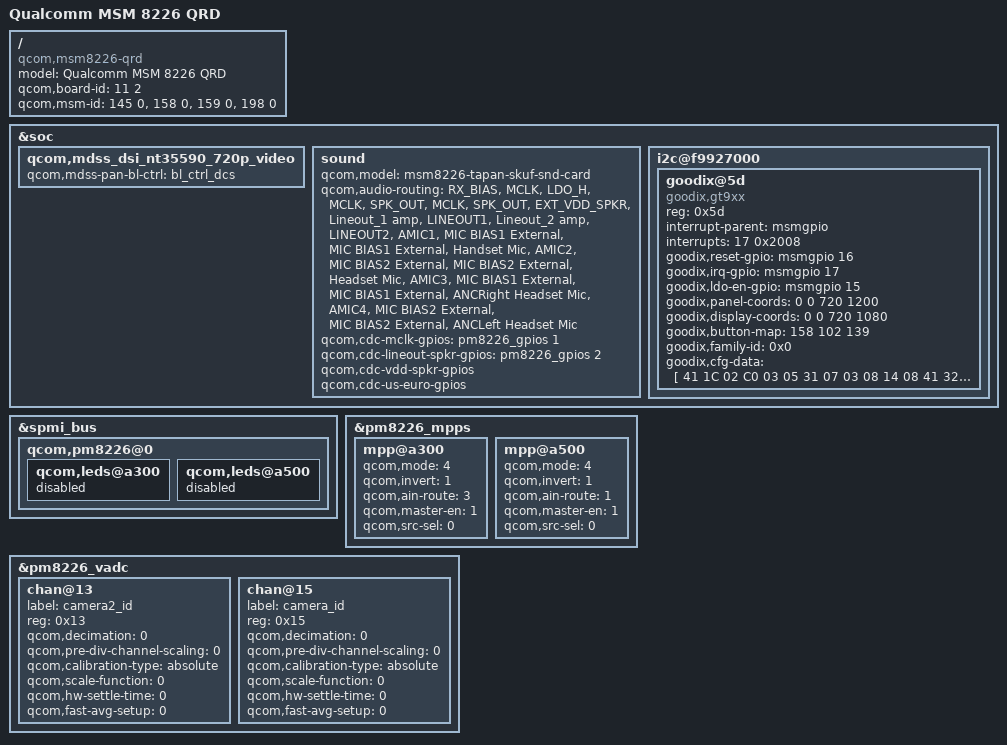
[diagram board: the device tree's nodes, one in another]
/* Copyright (c) 2013, The Linux Foundation. All rights reserved.
 *
 * This program is free software; you can redistribute it and/or modify
 * it under the terms of the GNU General Public License version 2 and
 * only version 2 as published by the Free Software Foundation.
 *
 * This program is distributed in the hope that it will be useful,
 * but WITHOUT ANY WARRANTY; without even the implied warranty of
 * MERCHANTABILITY or FITNESS FOR A PARTICULAR PURPOSE.  See the
 * GNU General Public License for more details.
 */

/dts-v1/;
/include/ "msm8226-v1.dtsi"
/include/ "msm8226-qrd.dtsi"
/include/ "dsi-panel-nt35590-720p-video.dtsi"

/ {
	model = "Qualcomm MSM 8226 QRD";
	compatible = "qcom,msm8226-qrd", "qcom,msm8226", "qcom,qrd";
	qcom,board-id = <11 2>;
	qcom,msm-id = <145 0>,
		      <158 0>,
		      <159 0>,
		      <198 0>;
};

&soc {
	qcom,mdss_dsi_nt35590_720p_video {
		status = "ok";
		qcom,mdss-pan-bl-ctrl = "bl_ctrl_dcs";
	};

	sound {
		qcom,model = "msm8226-tapan-skuf-snd-card";

		qcom,audio-routing =
			"RX_BIAS", "MCLK",
			"LDO_H", "MCLK",
			"SPK_OUT", "MCLK",
			"SPK_OUT", "EXT_VDD_SPKR",
			"Lineout_1 amp", "LINEOUT1",
			"Lineout_2 amp", "LINEOUT2",
			"AMIC1", "MIC BIAS1 External",
			"MIC BIAS1 External", "Handset Mic",
			"AMIC2", "MIC BIAS2 External",
			"MIC BIAS2 External", "Headset Mic",
			"AMIC3", "MIC BIAS1 External",
			"MIC BIAS1 External", "ANCRight Headset Mic",
			"AMIC4", "MIC BIAS2 External",
			"MIC BIAS2 External", "ANCLeft Headset Mic";

		qcom,cdc-mclk-gpios = <&pm8226_gpios 1 0>;
		qcom,cdc-lineout-spkr-gpios = <&pm8226_gpios 2 0>;
		qcom,cdc-vdd-spkr-gpios;
		qcom,cdc-us-euro-gpios;
	};

	i2c@f9927000 {
		goodix@5d {
			compatible = "goodix,gt9xx";
			reg = <0x5d>;
			interrupt-parent = <&msmgpio>;
			interrupts = <17 0x2008>;
			goodix,reset-gpio = <&msmgpio 16 0x00>;
			goodix,irq-gpio = <&msmgpio 17 0x00>;
			goodix,ldo-en-gpio = <&msmgpio 15 0x00>;
			goodix,panel-coords = <0 0 720 1200>;
			goodix,display-coords = <0 0 720 1080>;
			goodix,button-map= <158 102 139>;
			goodix,family-id = <0x0>;
			goodix,cfg-data = [
		41 1C 02 C0 03 05 31 07 03 08
		14 08 41 32 03 04 00 00 00 00
		00 00 00 18 1A 1E 14 8B 2B 0C
		1C 1E 8C 20 00 00 00 9A 03 2D
		00 00 00 00 00 00 00 00 00 22
		00 4B FA 94 85 02 05 00 00 E5
		1B 1A ED 1C 1C 3C 1F 1E 3C 1F
		24 08 27 1F 00 00 10 38 58 00
		67 60 45 FF FF 07 00 00 00 00
		00 01 06 14 0C 16 E8 03 02 00
		00 03 28 28 E5 00 23 23 00 00
		00 00 02 04 06 08 0A 0C 0E 10
		12 14 16 18 FF FF FF FF FF FF
		FF FF FF FF FF FF FF FF FF FF
		FF FF 00 02 04 06 08 0A 0C 0F
		10 12 13 16 18 1C 1D 1E 1F 20
		21 22 24 26 FF FF FF FF FF FF
		FF FF FF FF FF FF FF FF FF FF
		FF FF FF FF 90 01];
		};
	};
};

&spmi_bus {
	qcom,pm8226@0 {
		qcom,leds@a300 {
			status = "disabled";
		};

		qcom,leds@a500 {
			status = "disabled";
		};
	};
};

&pm8226_mpps {
	mpp@a300 { /* MPP 4 */
		/* camera2_id */
		qcom,mode = <4>; /* AIN input */
		qcom,invert = <1>; /* Enable MPP */
		qcom,ain-route = <3>; /* AMUX 8 */
		qcom,master-en = <1>;
		qcom,src-sel = <0>; /* Function constant */
	};

	mpp@a500 { /* MPP 6 */
		/* camera_id */
		qcom,mode = <4>; /* AIN input */
		qcom,invert = <1>; /* Enable MPP */
		qcom,ain-route = <1>; /* AMUX 6 */
		qcom,master-en = <1>;
		qcom,src-sel = <0>; /* Function constant */
	};

};

&pm8226_vadc {
	chan@13 {
		label = "camera2_id";
		reg = <0x13>;
		qcom,decimation = <0>;
		qcom,pre-div-channel-scaling = <0>;
		qcom,calibration-type = "absolute";
		qcom,scale-function = <0>;
		qcom,hw-settle-time = <0>;
		qcom,fast-avg-setup = <0>;
	};

	chan@15 {
		label = "camera_id";
		reg = <0x15>;
		qcom,decimation = <0>;
		qcom,pre-div-channel-scaling = <0>;
		qcom,calibration-type = "absolute";
		qcom,scale-function = <0>;
		qcom,hw-settle-time = <0>;
		qcom,fast-avg-setup = <0>;
	};
};
